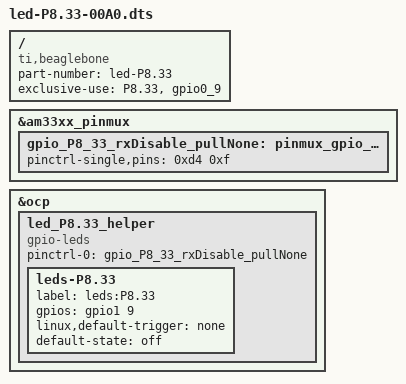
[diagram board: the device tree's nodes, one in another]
/*
* Easy gpio mux control of "P8.33" ("gpio0_9")
*/
/dts-v1/;
/plugin/;

/ {
	compatible = "ti,beaglebone", "ti,beaglebone-black";

	/* identification */
	part-number = "led-P8.33";
	/* version = "00A0"; */

	/* state the resources this cape uses */
	exclusive-use =
		/* the pin header uses */
		"P8.33",

		/* the hardware IP uses */
		"gpio0_9";
	
	
	/* rxDisable_pullNone state */
	fragment@0 {
		target = <&am33xx_pinmux>;
		__overlay__ {
			gpio_P8_33_rxDisable_pullNone: pinmux_gpio_P8.33_rxDisable_pullNone {
				pinctrl-single,pins = <
					0xd4 0xf
				>;
			};
		};
	};

	fragment@1 {
		target = <&ocp>;
		__overlay__ {
			led_P8.33_helper {
				compatible = "gpio-leds";
				pinctrl-names = "default";
				pinctrl-0 = <&gpio_P8_33_rxDisable_pullNone>;
				
				leds-P8.33 {
					label = "leds:P8.33";
					gpios = <&gpio1 9 0>;
					linux,default-trigger = "none";
					default-state = "off";
				};
			};
			
		};
	};

};
